# VPAC0_COMMON_0_IVPAC_TOP_0_CFG_SLV_DRU_UTC_VPAC0_DRU_MMR_CFG_DRU_DRU_CHATOMIC_DEBUG register map
Vendor: Texas Instruments
Peripheral module from a debugger description file (folder am62A).
Registers are 64-bit, read-only, reset 0x0 unless marked. A register's access mark holds for its fields unless they carry their own. Offsets are as the file gives them; lines under a group give offsets from that group; [hi:lo] are bit positions; {n}, {i} and the like mark numbered series; 'fields as' and 'values as' point back to an identical list; <NAME> marks a mode.

## VPAC0_COMMON_0_IVPAC_TOP_0_CFG_SLV_DRU_UTC_VPAC0_DRU_MMR_CFG_DRU_DRU_CHATOMIC_DEBUG
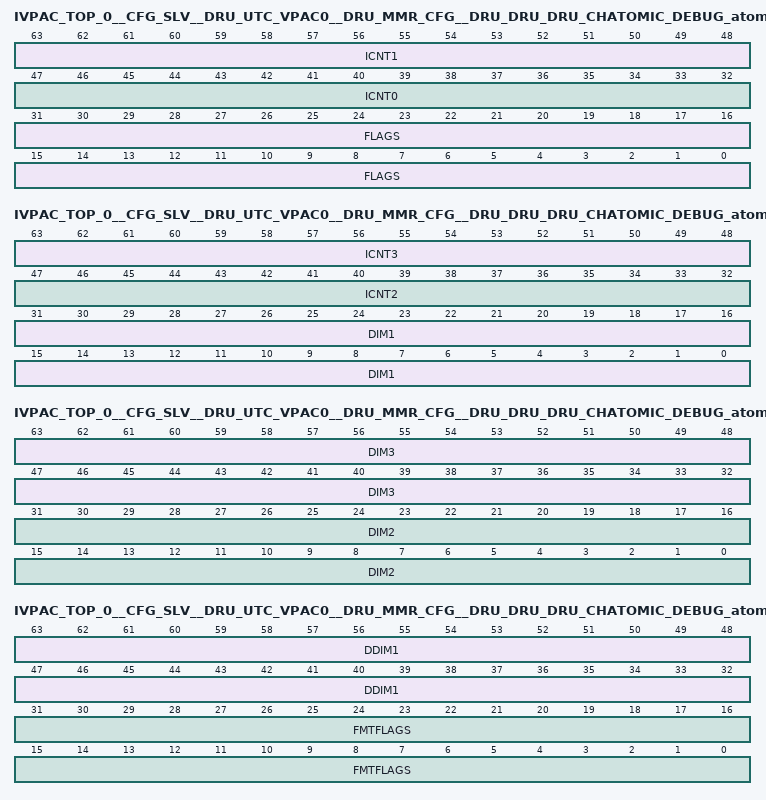
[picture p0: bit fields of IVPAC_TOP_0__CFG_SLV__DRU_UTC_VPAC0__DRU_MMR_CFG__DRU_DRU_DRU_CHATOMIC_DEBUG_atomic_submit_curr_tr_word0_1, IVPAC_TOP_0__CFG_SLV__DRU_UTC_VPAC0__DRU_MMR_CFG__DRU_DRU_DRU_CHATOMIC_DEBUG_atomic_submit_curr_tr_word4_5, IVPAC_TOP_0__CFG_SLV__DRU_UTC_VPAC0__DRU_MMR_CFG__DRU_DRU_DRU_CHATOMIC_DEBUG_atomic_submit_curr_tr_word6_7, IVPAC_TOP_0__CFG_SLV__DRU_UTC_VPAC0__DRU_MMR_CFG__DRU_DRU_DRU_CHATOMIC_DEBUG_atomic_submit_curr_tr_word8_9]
0x00 IVPAC_TOP_0__CFG_SLV__DRU_UTC_VPAC0__DRU_MMR_CFG__DRU_DRU_DRU_CHATOMIC_DEBUG_atomic_submit_curr_tr_word0_1 — The first TR submission word
  [63:48] ICNT1 — Lines in a transfer
  [47:32] ICNT0 — Bytes in a transfer
  [31:0] FLAGS — Flags for the operation and type of descriptor
0x08 IVPAC_TOP_0__CFG_SLV__DRU_UTC_VPAC0__DRU_MMR_CFG__DRU_DRU_DRU_CHATOMIC_DEBUG_atomic_submit_curr_tr_word2_3 — The second TR submission word
  [47:0] SRC_ADDR — Source transfer address virtual or physical allowed
0x10 IVPAC_TOP_0__CFG_SLV__DRU_UTC_VPAC0__DRU_MMR_CFG__DRU_DRU_DRU_CHATOMIC_DEBUG_atomic_submit_curr_tr_word4_5 — The third TR submission word
  [63:48] ICNT3 — The size of the 4th loop in the TR transfer
  [47:32] ICNT2 — The size of the 3rd loop in the TR transfer
  [31:0] DIM1 — The first dimension width of the source data
0x18 IVPAC_TOP_0__CFG_SLV__DRU_UTC_VPAC0__DRU_MMR_CFG__DRU_DRU_DRU_CHATOMIC_DEBUG_atomic_submit_curr_tr_word6_7 — The fourth TR submission word
  [63:32] DIM3 — The third dimension width of the source data
  [31:0] DIM2 — The second dimension width of the source data
0x20 IVPAC_TOP_0__CFG_SLV__DRU_UTC_VPAC0__DRU_MMR_CFG__DRU_DRU_DRU_CHATOMIC_DEBUG_atomic_submit_curr_tr_word8_9 — The fifth TR submission word
  [63:32] DDIM1 — The first dimension width of the destination data
  [31:0] FMTFLAGS — The data formatting flags to be used for the TR
0x28 IVPAC_TOP_0__CFG_SLV__DRU_UTC_VPAC0__DRU_MMR_CFG__DRU_DRU_DRU_CHATOMIC_DEBUG_atomic_submit_curr_tr_word10_11 — The sixth TR submission word
  [47:0] DADDR — Destination transfer address virtual or physical allowed
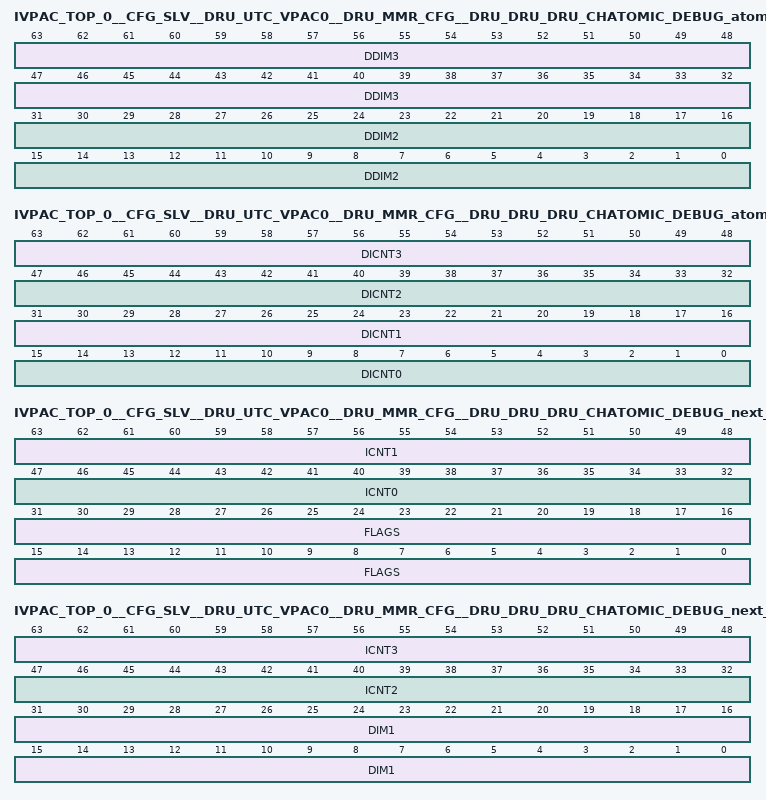
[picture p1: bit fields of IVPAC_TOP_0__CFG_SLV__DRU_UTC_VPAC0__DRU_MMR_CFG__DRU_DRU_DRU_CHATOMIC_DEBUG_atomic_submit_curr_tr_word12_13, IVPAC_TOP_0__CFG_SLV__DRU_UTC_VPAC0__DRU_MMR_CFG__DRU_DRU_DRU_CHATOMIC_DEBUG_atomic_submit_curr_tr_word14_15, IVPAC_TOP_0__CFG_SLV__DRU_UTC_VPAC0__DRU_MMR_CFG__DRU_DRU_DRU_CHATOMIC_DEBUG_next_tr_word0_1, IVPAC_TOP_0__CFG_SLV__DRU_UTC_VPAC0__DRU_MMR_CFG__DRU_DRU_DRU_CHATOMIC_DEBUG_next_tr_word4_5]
0x30 IVPAC_TOP_0__CFG_SLV__DRU_UTC_VPAC0__DRU_MMR_CFG__DRU_DRU_DRU_CHATOMIC_DEBUG_atomic_submit_curr_tr_word12_13 — The seventh TR submission word
  [63:32] DDIM3 — The third dimension width of the destination data
  [31:0] DDIM2 — The second dimension width of the destination data
0x38 IVPAC_TOP_0__CFG_SLV__DRU_UTC_VPAC0__DRU_MMR_CFG__DRU_DRU_DRU_CHATOMIC_DEBUG_atomic_submit_curr_tr_word14_15 — The eight TR submission word
  [63:48] DICNT3 — The fourth count of the destination if different than the source
  [47:32] DICNT2 — The third count of the destination if different than the source
  [31:16] DICNT1 — The second innermost count of the destination if different than the source
  [15:0] DICNT0 — The innermost count of the destination if different than the source
0x40 IVPAC_TOP_0__CFG_SLV__DRU_UTC_VPAC0__DRU_MMR_CFG__DRU_DRU_DRU_CHATOMIC_DEBUG_next_tr_word0_1 — The first TR submission word
  fields as IVPAC_TOP_0__CFG_SLV__DRU_UTC_VPAC0__DRU_MMR_CFG__DRU_DRU_DRU_CHATOMIC_DEBUG_atomic_submit_curr_tr_word0_1
0x48 IVPAC_TOP_0__CFG_SLV__DRU_UTC_VPAC0__DRU_MMR_CFG__DRU_DRU_DRU_CHATOMIC_DEBUG_next_tr_word2_3 — The second TR submission word
  fields as IVPAC_TOP_0__CFG_SLV__DRU_UTC_VPAC0__DRU_MMR_CFG__DRU_DRU_DRU_CHATOMIC_DEBUG_atomic_submit_curr_tr_word2_3
0x50 IVPAC_TOP_0__CFG_SLV__DRU_UTC_VPAC0__DRU_MMR_CFG__DRU_DRU_DRU_CHATOMIC_DEBUG_next_tr_word4_5 — The third TR submission word
  fields as IVPAC_TOP_0__CFG_SLV__DRU_UTC_VPAC0__DRU_MMR_CFG__DRU_DRU_DRU_CHATOMIC_DEBUG_atomic_submit_curr_tr_word4_5
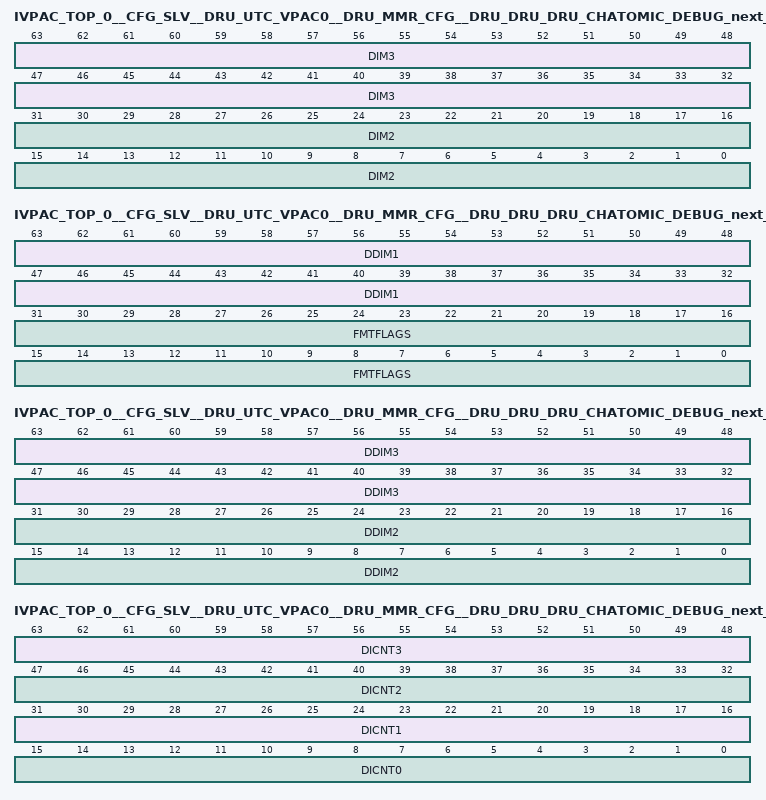
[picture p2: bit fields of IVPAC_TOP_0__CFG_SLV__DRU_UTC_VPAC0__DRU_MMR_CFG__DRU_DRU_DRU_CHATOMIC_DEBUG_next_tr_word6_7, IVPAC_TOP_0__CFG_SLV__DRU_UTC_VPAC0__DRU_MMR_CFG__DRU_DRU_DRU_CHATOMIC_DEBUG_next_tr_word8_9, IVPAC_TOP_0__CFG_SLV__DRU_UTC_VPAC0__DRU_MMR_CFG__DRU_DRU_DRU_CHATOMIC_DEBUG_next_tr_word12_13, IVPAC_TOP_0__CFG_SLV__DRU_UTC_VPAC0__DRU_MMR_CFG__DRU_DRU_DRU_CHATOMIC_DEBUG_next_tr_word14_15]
0x58 IVPAC_TOP_0__CFG_SLV__DRU_UTC_VPAC0__DRU_MMR_CFG__DRU_DRU_DRU_CHATOMIC_DEBUG_next_tr_word6_7 — The fourth TR submission word
  fields as IVPAC_TOP_0__CFG_SLV__DRU_UTC_VPAC0__DRU_MMR_CFG__DRU_DRU_DRU_CHATOMIC_DEBUG_atomic_submit_curr_tr_word6_7
0x60 IVPAC_TOP_0__CFG_SLV__DRU_UTC_VPAC0__DRU_MMR_CFG__DRU_DRU_DRU_CHATOMIC_DEBUG_next_tr_word8_9 — The fifth TR submission word
  fields as IVPAC_TOP_0__CFG_SLV__DRU_UTC_VPAC0__DRU_MMR_CFG__DRU_DRU_DRU_CHATOMIC_DEBUG_atomic_submit_curr_tr_word8_9
0x68 IVPAC_TOP_0__CFG_SLV__DRU_UTC_VPAC0__DRU_MMR_CFG__DRU_DRU_DRU_CHATOMIC_DEBUG_next_tr_word10_11 — The sixth TR submission word
  fields as IVPAC_TOP_0__CFG_SLV__DRU_UTC_VPAC0__DRU_MMR_CFG__DRU_DRU_DRU_CHATOMIC_DEBUG_atomic_submit_curr_tr_word10_11
0x70 IVPAC_TOP_0__CFG_SLV__DRU_UTC_VPAC0__DRU_MMR_CFG__DRU_DRU_DRU_CHATOMIC_DEBUG_next_tr_word12_13 — The seventh TR submission word
  fields as IVPAC_TOP_0__CFG_SLV__DRU_UTC_VPAC0__DRU_MMR_CFG__DRU_DRU_DRU_CHATOMIC_DEBUG_atomic_submit_curr_tr_word12_13
0x78 IVPAC_TOP_0__CFG_SLV__DRU_UTC_VPAC0__DRU_MMR_CFG__DRU_DRU_DRU_CHATOMIC_DEBUG_next_tr_word14_15 — The eight TR submission word
  fields as IVPAC_TOP_0__CFG_SLV__DRU_UTC_VPAC0__DRU_MMR_CFG__DRU_DRU_DRU_CHATOMIC_DEBUG_atomic_submit_curr_tr_word14_15
